# SAM9X75D5M device description
Architecture: ARM926EJ-S; Family: SAM9; Series: SAM9X7
Registers are 32-bit, read-write, reset 0x0 unless marked. A register's access mark holds for its fields unless they carry their own. Offsets are from the block's base; [hi:lo] are bit positions; lines under a group give offsets from that group; {n}, {i} and the like mark numbered series; 'fields as' and 'values as' point back to an identical list.

## MATRIX — AHB Bus Matrix
Instances: MATRIX 0xFFFFDE00
{0x0+4i} MATRIX_MCFG[{i}] (i=0..14) reset 0x4 — Master Configuration Register x
  [2:0] ULBT — Undefined Length Burst Type
    0=UNLIMITED (Unlimited Length Burst-No predicted end of burst is generated, therefore INCR bursts coming from this master can only be broken if the Slave Slot Cycle Limit is reached. If the Slot Cycle Limit is not reached, the burst is normally completed by the master, at the latest, on the next system bus 1 Kbyte address boundary, allowing up to 256-beat word bursts or 128-beat double-word bursts. This value should not be used in the very particular case of a master capable of performing back-to-back undefined length bursts on a single slave, since this could indefinitely freeze the slave arbitration and thus prevent another master from accessing this slave.); 1=SINGLE (Single Access-The undefined length burst is treated as a succession of single accesses, allowing re-arbitration at each beat of the INCR burst or bursts sequence.); 2=4_BEAT (4-beat Burst-The undefined length burst or bursts sequence is split into 4-beat bursts or less, allowing re-arbitration every 4 beats.); 3=8_BEAT (8-beat Burst-The undefined length burst or bursts sequence is split into 8-beat bursts or less, allowing re-arbitration every 8 beats.); 4=16_BEAT (16-beat Burst-The undefined length burst or bursts sequence is split into 16-beat bursts or less, allowing re-arbitration every 16 beats.); 5=32_BEAT (32-beat Burst-The undefined length burst or bursts sequence is split into 32-beat bursts or less, allowing re-arbitration every 32 beats.); 6=64_BEAT (64-beat Burst-The undefined length burst or bursts sequence is split into 64-beat bursts or less, allowing re-arbitration every 64 beats.); 7=128_BEAT (128-beat Burst-The undefined length burst or bursts sequence is split into 128-beat bursts or less, allowing re-arbitration every 128 beats. Unless duly needed, the ULBT should be left at its default 0 value for power saving.)
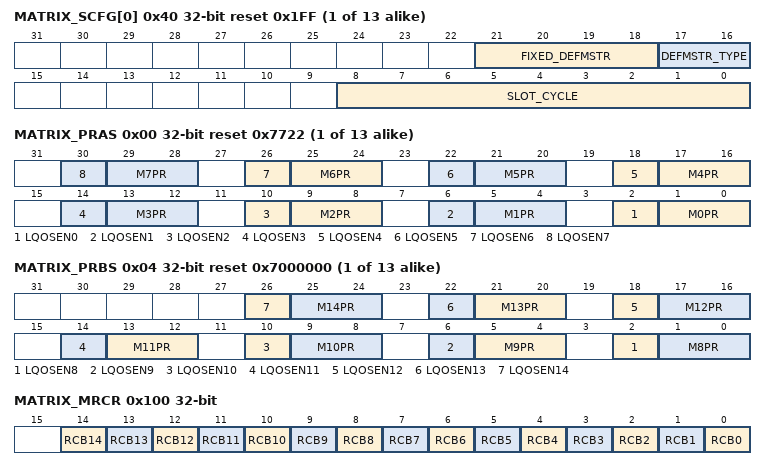
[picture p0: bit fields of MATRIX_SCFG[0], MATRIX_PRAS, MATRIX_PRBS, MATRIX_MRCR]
{0x40+4i} MATRIX_SCFG[{i}] (i=0..12) reset 0x1FF — Slave Configuration Register x
  [21:18] FIXED_DEFMSTR — Fixed Default Master
  [17:16] DEFMSTR_TYPE — Default Master Type
    0=NONE (No Default Master-At the end of the current slave access, if no other master request is pending, the slave is disconnected from all masters. This results in a one clock cycle latency for the first access of a burst transfer or for a single access.); 1=LAST (Last Default Master-At the end of the current slave access, if no other master request is pending, the slave stays connected to the last master having accessed it. This results in not having one clock cycle latency when the last master tries to access the slave again.); 2=FIXED (Fixed Default Master-At the end of the current slave access, if no other master request is pending, the slave connects to the fixed master the number that has been written in the FIXED_DEFMSTR field. This results in not having one clock cycle latency when the fixed master tries to access the slave again.)
  [8:0] SLOT_CYCLE — Maximum Bus Grant Duration for Masters
{0x80+8i} MATRIX_PR[{i}] (i=0..12) group
  0x00 MATRIX_PRAS reset 0x7722 — Priority Register A for Slave x
    [4n+2] LQOSEN{n} (n=0..7) — Latency Quality of Service Enable for Master {n}
      0=Disables propagation of Latency Quality of Service from the Master x to the Slave and apply MxPR priority for all access from Master x to the Slave; 1=Enables the propagation of Latency Quality of Service from the Master x to the Slave if supported by the Master x
    [4n+1:4n] M{n}PR (n=0..7) — Master {n} Priority
  0x04 MATRIX_PRBS reset 0x7000000 — Priority Register B for Slave x
    [4n-30] LQOSEN{n} (n=8..14) — Latency Quality of Service Enable for Master {n}
      values as MATRIX_PR[0].MATRIX_PRAS.LQOSEN0
    [4n-31:4n-32] M{n}PR (n=8..14) — Master {n} Priority
0x100 MATRIX_MRCR — Master Remap Control Register
  [all] fields
    0=Disables remapped address decoding for the selected Master; 1=Enables remapped address decoding for the selected Master
  [n] RCB{n} (n=0..14) — Remap Command Bit for Master {n}
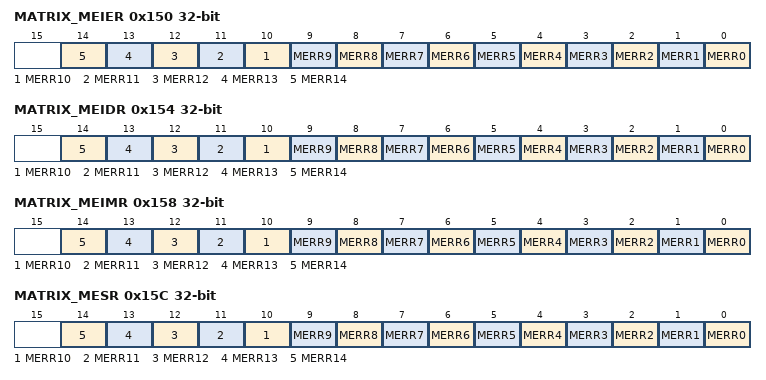
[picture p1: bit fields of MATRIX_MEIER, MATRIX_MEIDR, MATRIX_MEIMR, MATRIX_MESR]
0x150 MATRIX_MEIER wo reset not defined (atomic set of MATRIX_MEIMR) — Master Error Interrupt Enable Register
  [all] fields
    0=No effect; 1=Enables Master x Access Error interrupt source
  [n] MERR{n} (n=0..14) — Master {n} Access Error
0x154 MATRIX_MEIDR wo reset not defined (atomic clear of MATRIX_MEIMR) — Master Error Interrupt Disable Register
  [all] fields
    0=No effect; 1=Disables Master x Access Error interrupt source
  [n] MERR{n} (n=0..14) — Master {n} Access Error
0x158 MATRIX_MEIMR ro — Master Error Interrupt Mask Register
  [all] fields
    0=Master x Access Error does not trigger any interrupt; 1=Master x Access Error triggers the MATRIX interrupt line
  [n] MERR{n} (n=0..14) — Master {n} Access Error
0x15C MATRIX_MESR ro — Master Error Status Register
  [all] fields
    0=No Master Access Error has occurred since the last read of the MATRIX_MESR; 1=At least one Master Access Error has occurred since the last read of the MATRIX_MESR
  [n] MERR{n} (n=0..14) — Master {n} Access Error
{0x160+4i} MATRIX_MEAR[{i}] (i=0..14) ro — Master x Error Address Register
  [31:0] ERRADD — Master Error Address
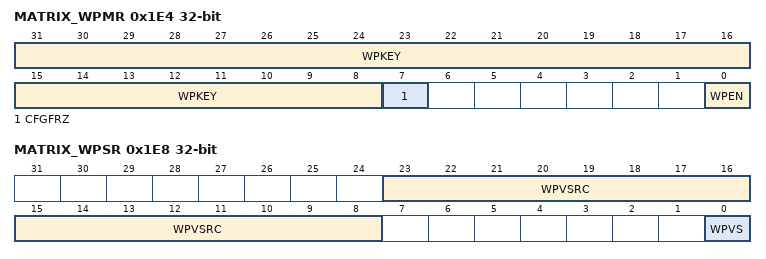
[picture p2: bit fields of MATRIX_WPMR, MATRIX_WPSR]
0x1E4 MATRIX_WPMR — Write Protect Mode Register
  [31:8] WPKEY — Write Protection Key
    0x4D4154=PASSWD (Writing any other value in this field aborts the write operation of the WPEN and CFGFRZ bits. Always reads as 0.)
  [7] CFGFRZ — Configuration Freeze
    0=The MATRIX configuration is not frozen; 1=Freezes the MATRIX configuration until hardware reset. The registers that can be protected by the WPEN bit and the Write Protection Mode Register are no longer modifiable.
  [0] WPEN — Write Protection Enable
    0=Disables the write protection if WPKEY corresponds to 0x4D4154 ("MAT" in ASCII); 1=Enables the write protection if WPKEY corresponds to 0x4D4154 ("MAT" in ASCII)
0x1E8 MATRIX_WPSR ro — Write Protect Status Register
  [23:8] WPVSRC — Write Protection Violation Source
  [0] WPVS — Write Protection Violation Status
    0=No write protection violation has occurred since the last write of the MATRIX_WPMR; 1=A write protection violation has occurred since the last write of the MATRIX_WPMR. If this violation is an unauthorized attempt to write a protected register, the associated violation is reported into field WPVSRC.

## Notices in the file
Copyright (c) 2021 Microchip Technology Inc.
SPDX-License-Identifier: Apache-2.0
Licensed under the Apache License, Version 2.0 (the "License");
you may not use this file except in compliance with the License.
You may obtain a copy of the License at
http://www.apache.org/licenses/LICENSE-2.0
Unless required by applicable law or agreed to in writing, software
distributed under the License is distributed on an "AS IS" BASIS,
WITHOUT WARRANTIES OR CONDITIONS OF ANY KIND, either express or implied.
See the License for the specific language governing permissions and
limitations under the License.
